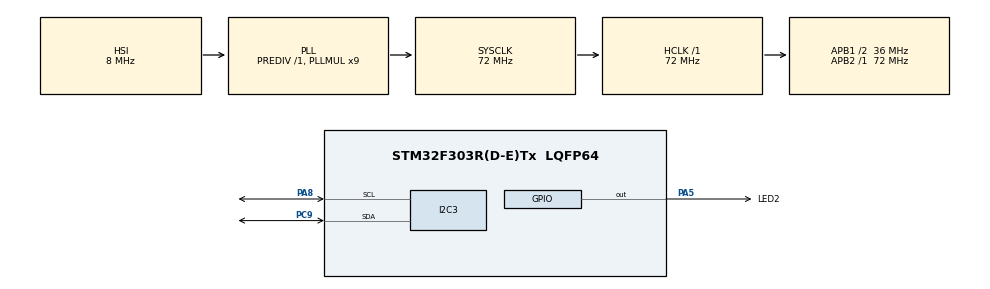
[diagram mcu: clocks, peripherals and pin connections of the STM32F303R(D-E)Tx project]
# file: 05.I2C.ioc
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I2C3.Analog_Filter=I2C_ANALOGFILTER_ENABLE
I2C3.Timing=0x2000090E
Mcu.Family=STM32F3
Mcu.Name=STM32F303R(D-E)Tx
Mcu.Package=LQFP64
NVIC.PriorityGroup=NVIC_PRIORITYGROUP_4
PA13.Mode=Serial_Wire
PA13.Signal=SYS_JTMS-SWDIO
PA14.Mode=Serial_Wire
PA14.Signal=SYS_JTCK-SWCLK
PA5.GPIO_Label=LED2
PA5.Signal=GPIO_Output
PA8.GPIO_PuPdOD=GPIO_NOPULL
PA8.Mode=I2C
PA8.Signal=I2C3_SCL
PC9.GPIO_PuPdOD=GPIO_NOPULL
PC9.Mode=I2C
PC9.Signal=I2C3_SDA
ProjectManager.HeapSize=0x200
ProjectManager.StackSize=0x400
ProjectManager.TargetToolchain=STM32CubeIDE
RCC.AHBFreq_Value=72000000
RCC.APB1CLKDivider=RCC_HCLK_DIV2
RCC.APB1Freq_Value=36000000
RCC.APB1TimFreq_Value=72000000
RCC.APB2Freq_Value=72000000
RCC.APB2TimFreq_Value=72000000
RCC.CortexFreq_Value=72000000
RCC.HCLKFreq_Value=72000000
RCC.HSE_VALUE=8000000
RCC.HSI_VALUE=8000000
RCC.LSE_VALUE=32768
RCC.PLLMUL=RCC_PLL_MUL9
RCC.SYSCLKFreq_VALUE=72000000
RCC.SYSCLKSourceVirtual=RCC_SYSCLKSOURCE_PLLCLK
RCC.USBFreq_Value=72000000
board=custom

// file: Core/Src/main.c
/* USER CODE BEGIN Header */
/**
  ******************************************************************************
  * @file           : main.c
  * @brief          : Main program body
  ******************************************************************************
  * @attention
  *
  * <h2><center>&copy; Copyright (c) 2020 STMicroelectronics.
  * All rights reserved.</center></h2>
  *
  * This software component is licensed by ST under BSD 3-Clause license,
  * the "License"; You may not use this file except in compliance with the
  * License. You may obtain a copy of the License at:
  *                        opensource.org/licenses/BSD-3-Clause
  *
  ******************************************************************************
  */
/* USER CODE END Header */

#include "main.h"

I2C_HandleTypeDef hi2c3;

void SystemClock_Config(void);
static void MX_GPIO_Init(void);
static void MX_I2C3_Init(void);

int main(void)
{

  /* MCU Configuration--------------------------------------------------------*/

  /* Reset of all peripherals, Initializes the Flash interface and the Systick. */
  HAL_Init();

  /* Configure the system clock */
  SystemClock_Config();

  /* Initialize all configured peripherals */
  MX_GPIO_Init();
  MX_I2C3_Init();
  /* USER CODE BEGIN 2 */
  HAL_Delay(2000);
  HAL_StatusTypeDef ret;
  uint8_t data[1];
  if(HAL_OK == HAL_I2C_IsDeviceReady(&hi2c3, 0x49, 2, 10))
  {
	  HAL_GPIO_TogglePin(LED2_GPIO_Port, LED2_Pin);
  }

  /* USER CODE END 2 */

  /* Infinite loop */
  while (1)
  {

    /* USER CODE BEGIN 3 */
	ret = HAL_I2C_Master_Receive(&hi2c3, (uint16_t)(0x24<<1)|0x01, data, 1, 5000);
	if (ret != HAL_OK)
	{
		printf("error");
	}

	switch (data[0]) {
		case 247:
			HAL_GPIO_TogglePin(LED2_GPIO_Port, LED2_Pin);
			HAL_Delay(100);
			break;
		case 251:
			HAL_GPIO_TogglePin(LED2_GPIO_Port, LED2_Pin);
			HAL_Delay(300);
			break;
		case 253:
			HAL_GPIO_TogglePin(LED2_GPIO_Port, LED2_Pin);
			HAL_Delay(500);
			break;
		case 254:
			HAL_GPIO_TogglePin(LED2_GPIO_Port, LED2_Pin);
			HAL_Delay(700);
			break;
		default:
			break;
	}

	HAL_Delay(100);
  }
  /* USER CODE END 3 */
}

void SystemClock_Config(void)
{
  RCC_OscInitTypeDef RCC_OscInitStruct = {0};
  RCC_ClkInitTypeDef RCC_ClkInitStruct = {0};
  RCC_PeriphCLKInitTypeDef PeriphClkInit = {0};

  /** Initializes the CPU, AHB and APB busses clocks
  */
  RCC_OscInitStruct.OscillatorType = RCC_OSCILLATORTYPE_HSI;
  RCC_OscInitStruct.HSIState = RCC_HSI_ON;
  RCC_OscInitStruct.HSICalibrationValue = RCC_HSICALIBRATION_DEFAULT;
  RCC_OscInitStruct.PLL.PLLState = RCC_PLL_ON;
  RCC_OscInitStruct.PLL.PLLSource = RCC_PLLSOURCE_HSI;
  RCC_OscInitStruct.PLL.PLLMUL = RCC_PLL_MUL9;
  RCC_OscInitStruct.PLL.PREDIV = RCC_PREDIV_DIV1;
  if (HAL_RCC_OscConfig(&RCC_OscInitStruct) != HAL_OK)
  {
    Error_Handler();
  }
  /** Initializes the CPU, AHB and APB busses clocks
  */
  RCC_ClkInitStruct.ClockType = RCC_CLOCKTYPE_HCLK|RCC_CLOCKTYPE_SYSCLK
                              |RCC_CLOCKTYPE_PCLK1|RCC_CLOCKTYPE_PCLK2;
  RCC_ClkInitStruct.SYSCLKSource = RCC_SYSCLKSOURCE_PLLCLK;
  RCC_ClkInitStruct.AHBCLKDivider = RCC_SYSCLK_DIV1;
  RCC_ClkInitStruct.APB1CLKDivider = RCC_HCLK_DIV2;
  RCC_ClkInitStruct.APB2CLKDivider = RCC_HCLK_DIV1;

  if (HAL_RCC_ClockConfig(&RCC_ClkInitStruct, FLASH_LATENCY_2) != HAL_OK)
  {
    Error_Handler();
  }
  PeriphClkInit.PeriphClockSelection = RCC_PERIPHCLK_I2C3;
  PeriphClkInit.I2c3ClockSelection = RCC_I2C3CLKSOURCE_HSI;
  if (HAL_RCCEx_PeriphCLKConfig(&PeriphClkInit) != HAL_OK)
  {
    Error_Handler();
  }
}

static void MX_I2C3_Init(void)
{

  hi2c3.Instance = I2C3;
  hi2c3.Init.Timing = 0x2000090E;
  hi2c3.Init.OwnAddress1 = 0;
  hi2c3.Init.AddressingMode = I2C_ADDRESSINGMODE_7BIT;
  hi2c3.Init.DualAddressMode = I2C_DUALADDRESS_DISABLE;
  hi2c3.Init.OwnAddress2 = 0;
  hi2c3.Init.OwnAddress2Masks = I2C_OA2_NOMASK;
  hi2c3.Init.GeneralCallMode = I2C_GENERALCALL_DISABLE;
  hi2c3.Init.NoStretchMode = I2C_NOSTRETCH_DISABLE;
  if (HAL_I2C_Init(&hi2c3) != HAL_OK)
  {
    Error_Handler();
  }
  /** Configure Analogue filter
  */
  if (HAL_I2CEx_ConfigAnalogFilter(&hi2c3, I2C_ANALOGFILTER_ENABLE) != HAL_OK)
  {
    Error_Handler();
  }
  /** Configure Digital filter
  */
  if (HAL_I2CEx_ConfigDigitalFilter(&hi2c3, 0) != HAL_OK)
  {
    Error_Handler();
  }

}

static void MX_GPIO_Init(void)
{
  GPIO_InitTypeDef GPIO_InitStruct = {0};

  /* GPIO Ports Clock Enable */
  __HAL_RCC_GPIOA_CLK_ENABLE();
  __HAL_RCC_GPIOC_CLK_ENABLE();

  /*Configure GPIO pin Output Level */
  HAL_GPIO_WritePin(LED2_GPIO_Port, LED2_Pin, GPIO_PIN_RESET);

  /*Configure GPIO pin : LED2_Pin */
  GPIO_InitStruct.Pin = LED2_Pin;
  GPIO_InitStruct.Mode = GPIO_MODE_OUTPUT_PP;
  GPIO_InitStruct.Pull = GPIO_NOPULL;
  GPIO_InitStruct.Speed = GPIO_SPEED_FREQ_LOW;
  HAL_GPIO_Init(LED2_GPIO_Port, &GPIO_InitStruct);

}

void Error_Handler(void)
{
}

/************************ (C) COPYRIGHT STMicroelectronics *****END OF FILE****/
